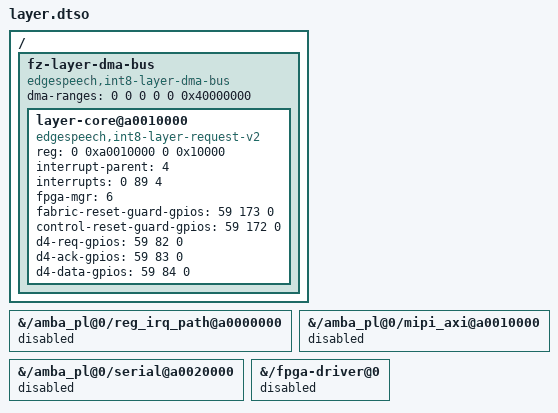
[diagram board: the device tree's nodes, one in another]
/dts-v1/;
/plugin/;
/ {
fragment@0 { target-path = "/amba_pl@0/reg_irq_path@a0000000"; __overlay__ { status = "disabled"; }; };
fragment@1 { target-path = "/amba_pl@0/mipi_axi@a0010000"; __overlay__ { status = "disabled"; }; };
fragment@2 { target-path = "/amba_pl@0/serial@a0020000"; __overlay__ { status = "disabled"; }; };
fragment@3 { target-path = "/fpga-driver@0"; __overlay__ { status = "disabled"; }; };
fragment@4 { target-path = "/"; __overlay__ { fz-layer-dma-bus {
        compatible = "edgespeech,int8-layer-dma-bus", "simple-bus";
        #address-cells=<2>; #size-cells=<2>;
        ranges=<0 0xa0010000 0 0xa0010000 0 0x10000>;
        dma-ranges=<0 0 0 0 0 0x40000000>;
        layer-core@a0010000 { compatible = "edgespeech,int8-layer-request-v2";
        reg = <0 0xa0010000 0 0x10000>;
        interrupt-parent = <4>; interrupts = <0 89 4>;
        fpga-mgr = <6>; fabric-reset-guard-gpios = <59 173 0>;
        control-reset-guard-gpios = <59 172 0>;
        d4-req-gpios = <59 82 0>; d4-ack-gpios = <59 83 0>; d4-data-gpios = <59 84 0>;
    }; }; }; }; };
